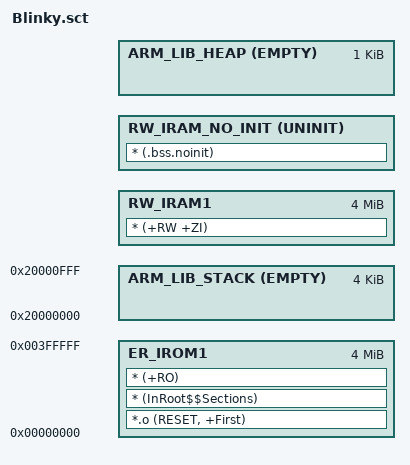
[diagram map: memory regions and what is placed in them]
#! armclang -E --target=arm-arm-none-eabi -mcpu=cortex-m33 -xc
; command above MUST be in first line (no comment above!)

#define __STACK_SIZE        0x1000
#define __HEAP_SIZE         0x0400

; *************************************************************
; *** Scatter-Loading Description File generated by uVision ***
; *************************************************************

LR_IROM1 0x00000000 0x00400000  {    ; load region size_region
    ER_IROM1 0x00000000 0x00400000  {  ; load address = execution address
        *.o (RESET, +First)
        *   (InRoot$$Sections)
        *   (+RO)
    }

    ; Reserve empty region for stack
    ARM_LIB_STACK 0x20000000 ALIGN 8 EMPTY __STACK_SIZE {         
    }

    RW_IRAM1 +0 0x00400000  {  ; RW data
        * (+RW +ZI)
    }
    RW_IRAM_NO_INIT +0 UNINIT {
        * (.bss.noinit)
    }

    ; Reserve empty region for heap
    ARM_LIB_HEAP  +0 ALIGN 8 EMPTY __HEAP_SIZE {                 
    }
}

